# VPAC0_COMMON_0_IVPAC_TOP_0_CFG_SLV_VPAC_REGS_VPAC_REGS_CFG_IP_MMRS register map
Vendor: Texas Instruments
Peripheral module from a debugger description file (folder am62A).
Registers are 32-bit, read-write, reset 0x0 unless marked. A register's access mark holds for its fields unless they carry their own. Offsets are as the file gives them; lines under a group give offsets from that group; [hi:lo] are bit positions; {n}, {i} and the like mark numbered series; 'fields as' and 'values as' point back to an identical list; <NAME> marks a mode.

## VPAC0_COMMON_0_IVPAC_TOP_0_CFG_SLV_VPAC_REGS_VPAC_REGS_CFG_IP_MMRS
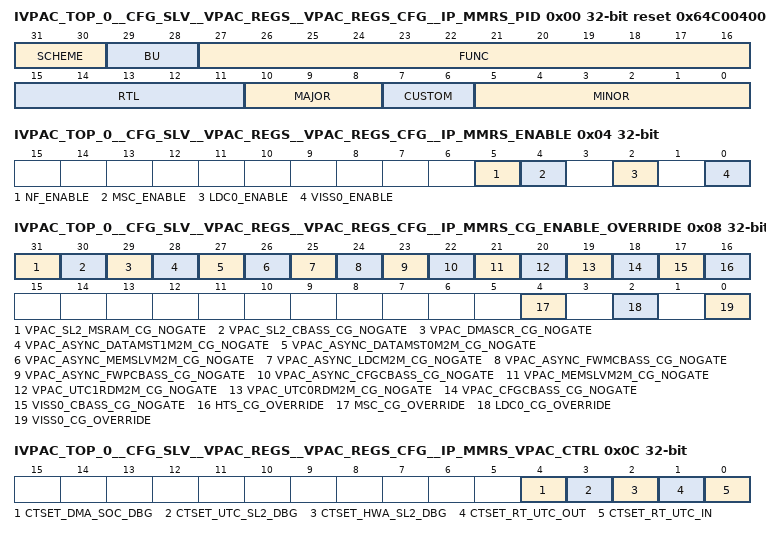
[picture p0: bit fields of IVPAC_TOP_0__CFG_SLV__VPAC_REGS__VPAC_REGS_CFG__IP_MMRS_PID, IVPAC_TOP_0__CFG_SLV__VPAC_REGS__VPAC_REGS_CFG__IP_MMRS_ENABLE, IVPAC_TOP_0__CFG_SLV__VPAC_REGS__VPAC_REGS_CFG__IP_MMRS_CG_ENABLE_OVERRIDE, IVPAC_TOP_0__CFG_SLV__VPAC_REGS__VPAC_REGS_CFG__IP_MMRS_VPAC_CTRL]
0x00 IVPAC_TOP_0__CFG_SLV__VPAC_REGS__VPAC_REGS_CFG__IP_MMRS_PID ro reset 0x64C00400 — VPAC PID
  [31:30] SCHEME — Used to distinguish between old scheme and new scheme. Spare bit to encode future schemes
  [29:28] BU — BU indicator DSPS ==> 0x0 WTBU ==> 0x1 Processors ==> 0x2
  [27:16] FUNC — Function indicates a software compatible module family. If there is no level of software compatibility a new FUNC number, and hence PID, should be assigned.
  [15:11] RTL — RTL Version. R as described in PDR with additional clarifications and definitions below. Must be easily ECO-able or controlled during fabrication. Ideally through a top level metal mask or e-fuse. This number is maintained/owned by IP design owner. RTL follows a numbering such as X.Y.R.Z which are explained in this table. R changes ONLY when: (1) PDS uploads occur which may have been due to spec changes (2) Bug fixes occur (3) Resets to '0' when X or Y changes. Design team has an internal 'Z' (customer invisible) number which increments on every drop that happens due to DV and RTL updates. Z resets to 0 when R increments.
  [10:8] MAJOR — Major Revision. X as described in PDR with additional clarifications/definitions below. This number is owned/maintained by IP specification owner. X is part of IP numbering X.Y.R.Z. X changes ONLY when: (1) There is a major feature addition. An example would be adding Master Mode to Utopia Level2. The Func field (or Class/Type in old PID format) will remain the same. X does NOT change due to: (1) Bug fixes (2) Change in feature parameters.
  [7:6] CUSTOM — Indicates a special version for a particular device. Consequence of use may avoid use of standard Chip Support Library (CSL) / Drivers. 0 if non-custom.
  [5:0] MINOR — Minor Revision. Y as described in PDR with additional clarifications/definitions below. This number is owned/maintained by IP specification owner. Y changes ONLY when: (1) Features are scaled (up or down). Flexibility exists in that this feature scalability may either be represented in the Y change or a specific register in the IP that indicates which features are exactly available. (2) When feature creeps from Is-Not list to Is list. But this may not be the case once it sees silicon - in which case X will change. Y does NOT change due to: (1) Bug fixes (2) Typos or clarifications (3) major functional/feature change/addition/deletion. Instead these changes may be reflected via R, S, X as applicable. Spec owner maintains a customer-invisible number 'S' which changes due to: (1) Typos/clarifications (2) Bug documentation. Note that this bug is not due to a spec change but due to implementation. Nevertheless, the spec tracks the IP bugs. An RTL release (say for silicon PG1.1) that occurs due to bug fix should document the corresponding spec number (X.Y.S) in its release notes.
0x04 IVPAC_TOP_0__CFG_SLV__VPAC_REGS__VPAC_REGS_CFG__IP_MMRS_ENABLE — VPAC accelerators Enable; used in clock gating accelerator when disabled. NOT SUPPORTED IN current VERSION
  [5] NF_ENABLE — '1' --> nf is enabled , '0' --> nf is disabled
  [4] MSC_ENABLE — '1' --> msc is enabled , '0' --> msc is disabled
  [2] LDC0_ENABLE — '1' --> ldc0 is enabled , '0' --> ldc0 is disabled
  [0] VISS0_ENABLE — '1' --> viss0 is enabled , '0' --> viss0 is disabled
0x08 IVPAC_TOP_0__CFG_SLV__VPAC_REGS__VPAC_REGS_CFG__IP_MMRS_CG_ENABLE_OVERRIDE reset 0x82000000 — Register to override the dynamic auto clock gating done in VPAC to reduce power.By default these bits are 0. it should be set to 1 only when we encounter some silicon bug.
  [31] VPAC_SL2_MSRAM_CG_NOGATE — '1' --> No clock gating in SL2 MSRAM, '0' --> auto clock gating enabled. Not to be used in this version of HW
  [30] VPAC_SL2_CBASS_CG_NOGATE — '1' --> No clock gating in SL2 MSRAM, '0' --> auto clock gating enabled.
  [29] VPAC_DMASCR_CG_NOGATE — '1' --> No clock gating in SL2 MSRAM, '0' --> auto clock gating enabled.
  [28] VPAC_ASYNC_DATAMST1M2M_CG_NOGATE — '1' --> No clock gating in data_mst1 async m2m, '0' --> auto clock gating enabled
  [27] VPAC_ASYNC_DATAMST0M2M_CG_NOGATE — '1' --> No clock gating in data_mst0 async m2m, '0' --> auto clock gating enabled
  [26] VPAC_ASYNC_MEMSLVM2M_CG_NOGATE — '1' --> No clock gating in mem_slv async m2m, '0' --> auto clock gating enabled
  [25] VPAC_ASYNC_LDCM2M_CG_NOGATE — '1' --> No clock gating in ldc_mst async m2m, '0' --> auto clock gating enabled
  [24] VPAC_ASYNC_FWMCBASS_CG_NOGATE — '1' --> No clock gating in vpac fw vbusm async cbass, '0' --> auto clock gating enabled.
  [23] VPAC_ASYNC_FWPCBASS_CG_NOGATE — '1' --> No clock gating in vpac fw vbusp async cbass, '0' --> auto clock gating enabled.
  [22] VPAC_ASYNC_CFGCBASS_CG_NOGATE — '1' --> No clock gating in vpac config async cbass, '0' --> auto clock gating enabled
  [21] VPAC_MEMSLVM2M_CG_NOGATE — '1' --> No clock gating in memslv rd reassembly m2m, '0' --> auto clock gating enabled
  [20] VPAC_UTC1RDM2M_CG_NOGATE — '1' --> No clock gating in utc1 rd reassembly m2m , '0' --> auto clock gating enabled.
  [19] VPAC_UTC0RDM2M_CG_NOGATE — '1' --> No clock gating in utc0 rd reassembly m2m , '0' --> auto clock gating enabled.
  [18] VPAC_CFGCBASS_CG_NOGATE — '1' --> No clock gating in vpac config cbass, '0' --> auto clock gating enabled
  [17] VISS0_CBASS_CG_NOGATE — '1' --> No clock gating in viss cbass, '0' --> auto clock gating enabled
  [16] HTS_CG_OVERRIDE — '1' --> clock gating override, '0' --> No clock gating override
  [4] MSC_CG_OVERRIDE — '1' --> clock gating override, '0' --> No clock gating override
  [2] LDC0_CG_OVERRIDE — '1' --> clock gating override, '0' --> No clock gating override
  [0] VISS0_CG_OVERRIDE — '1' --> clock gating override, '0' --> No clock gating override
0x0C IVPAC_TOP_0__CFG_SLV__VPAC_REGS__VPAC_REGS_CFG__IP_MMRS_VPAC_CTRL — Register to control and do event selection for VPAC module
  [4] CTSET_DMA_SOC_DBG — select config for CTSET[206:175] '0' --> select UTC utc_ctset_intr[31:0] , '1' --> Select ldc0_rd,NRT_ext,RT_ext master ports (sreq,rreq,creq stall,valid creq)
  [3] CTSET_UTC_SL2_DBG — select config for CTSET[254:239] '0' --> select ext_ctset_event[15:0] , '1' --> Select NRT_wr,NRT_rd,RT_wr,RT_rd master ports (sreq,rreq,creq stall,valid creq)
  [2] CTSET_HWA_SL2_DBG — select config for CTSET[142:111] '0' --> Select UTC utc_channel_start[31:0] , '1' --> Select nf,msc,ldc0,viss0 master ports (sreq,rreq,creq stall,valid creq)
  [1] CTSET_RT_UTC_OUT — select config for CTSET[238:207] '0' --> Select UTC utc_ctset_intr[63:32] , '1' --> Select UTC utc_ctset_intr[31:0]
  [0] CTSET_RT_UTC_IN — select config for CTSET[174:143] '0' --> Select UTC utc_channel_start[63:32] , '1' --> 32'b0
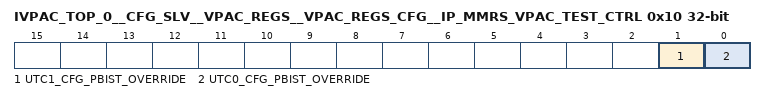
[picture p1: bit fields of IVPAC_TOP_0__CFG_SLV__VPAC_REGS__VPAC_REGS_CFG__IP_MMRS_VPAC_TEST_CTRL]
0x10 IVPAC_TOP_0__CFG_SLV__VPAC_REGS__VPAC_REGS_CFG__IP_MMRS_VPAC_TEST_CTRL — Register to control testing config
  [1] UTC1_CFG_PBIST_OVERRIDE — '1' --> Config pbist mode: forces UTC1 interface to allow free running clock to RAM during config PBIST , '0' --> FUNC mode
  [0] UTC0_CFG_PBIST_OVERRIDE — '1' --> Config pbist mode: forces UTC0 interface to allow free running clock to RAM during config PBIST , '0' --> FUNC mode
